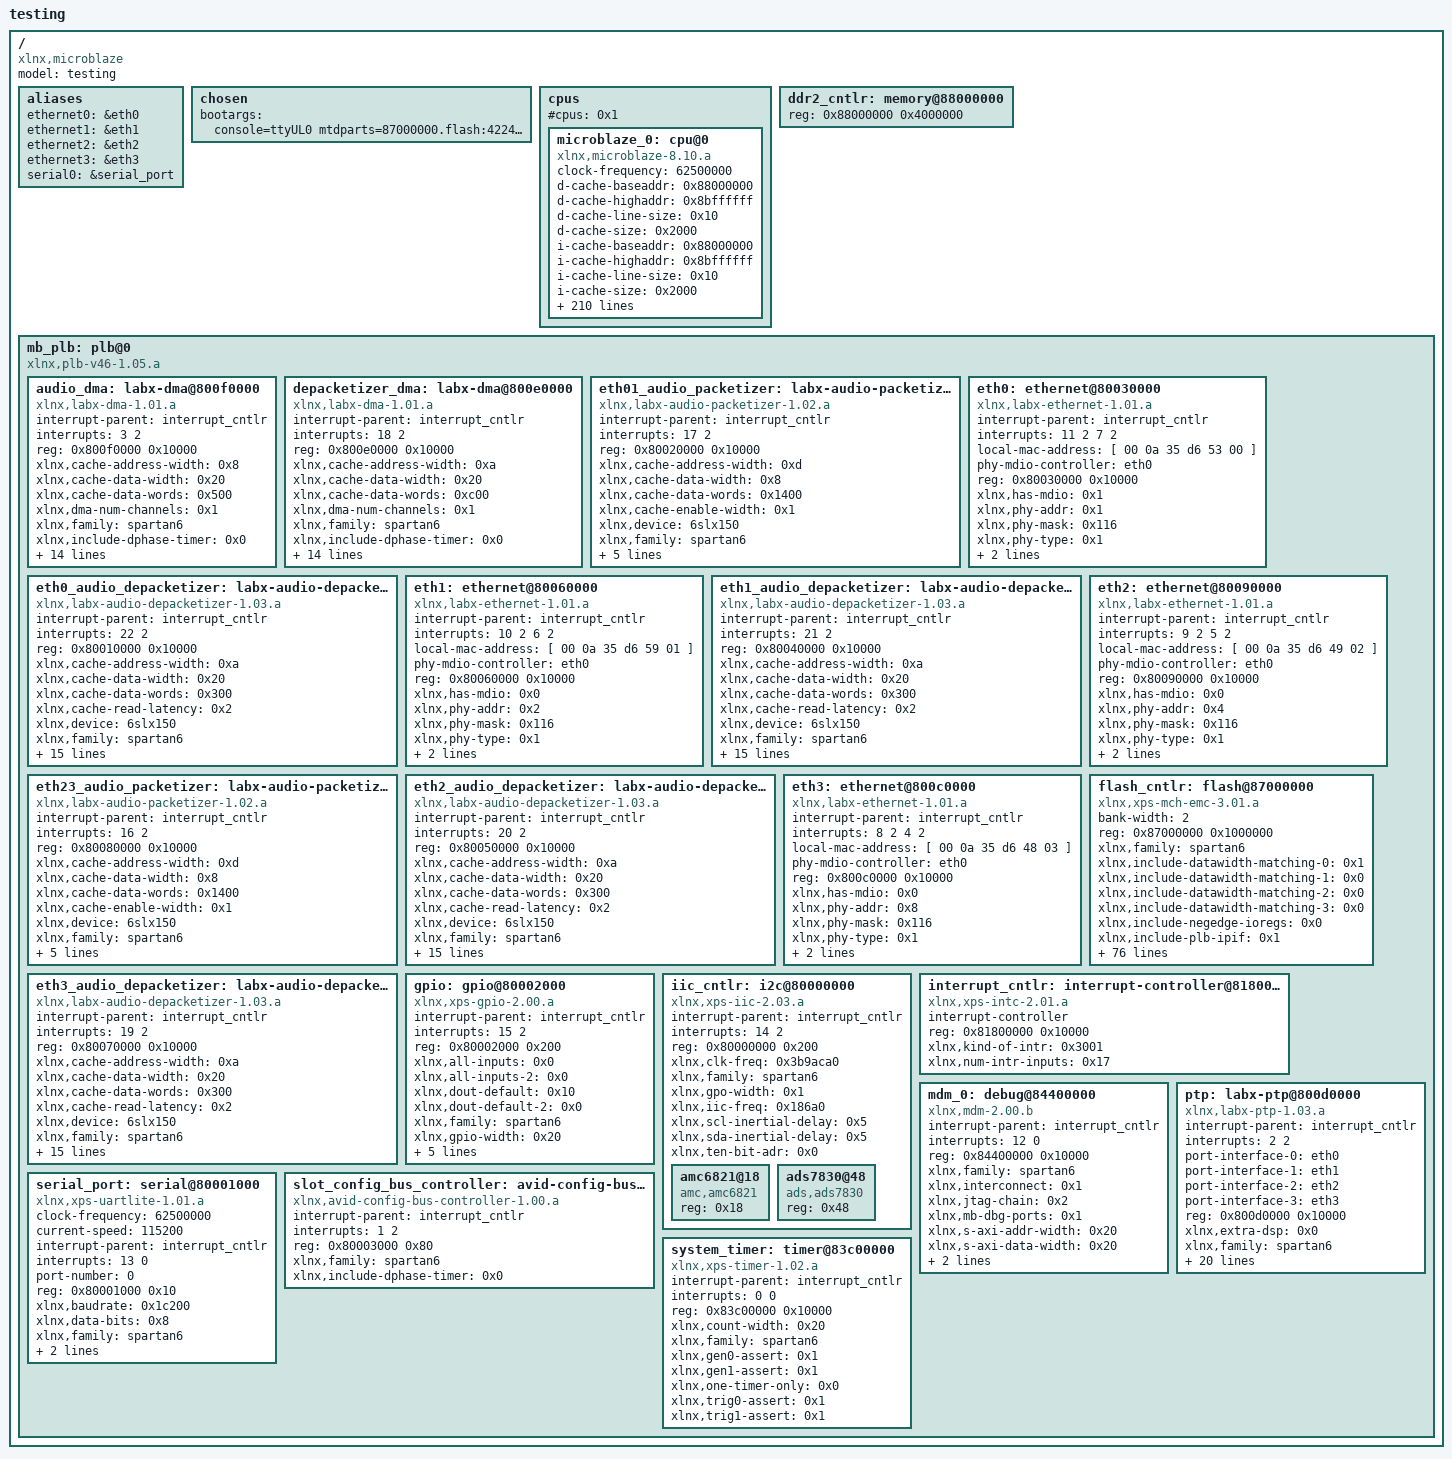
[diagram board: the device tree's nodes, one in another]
/*
 * Device Tree Generator version: 1.3
 *
 * (C) Copyright 2007-2008 Xilinx, Inc.
 * (C) Copyright 2007-2009 Michal Simek
 *
 * Michal SIMEK <monstr@monstr.eu>
 *
 * This program is free software; you can redistribute it and/or
 * modify it under the terms of the GNU General Public License as
 * published by the Free Software Foundation; either version 2 of
 * the License, or (at your option) any later version.
 *
 * This program is distributed in the hope that it will be useful,
 * but WITHOUT ANY WARRANTY; without even the implied warranty of
 * MERCHANTABILITY or FITNESS FOR A PARTICULAR PURPOSE. See the
 * GNU General Public License for more details.
 *
 * You should have received a copy of the GNU General Public License
 * along with this program; if not, write to the Free Software
 * Foundation, Inc., 59 Temple Place, Suite 330, Boston,
 * MA 02111-1307 USA
 *
 * CAUTION: This file is automatically generated by libgen.
 * Version: Xilinx EDK 13.1 EDK_O.40d
 *
 */

/dts-v1/;
/ {
	#address-cells = <1>;
	#size-cells = <1>;
	compatible = "xlnx,microblaze";
	model = "testing";
	aliases {
		ethernet0 = &eth0;
		ethernet1 = &eth1;
		ethernet2 = &eth2;
		ethernet3 = &eth3;
		serial0 = &serial_port;
	} ;
	chosen {
		bootargs = "console=ttyUL0 mtdparts=87000000.flash:4224K(fpga),256K(boot),128K(fdt),3712K(image),1920K(rootfs),3968K(romfs),2048K(settingsfs),32K(bootenv) root=mtd4 rootfstype=romfs init=/bin/init broadcom.led_default=0,0,-1,-1";
	} ;
	cpus {
		#address-cells = <1>;
		#cpus = <0x1>;
		#size-cells = <0>;
		microblaze_0: cpu@0 {
			clock-frequency = <62500000>;
			compatible = "xlnx,microblaze-8.10.a";
			d-cache-baseaddr = <0x88000000>;
			d-cache-highaddr = <0x8bffffff>;
			d-cache-line-size = <0x10>;
			d-cache-size = <0x2000>;
			device_type = "cpu";
			i-cache-baseaddr = <0x88000000>;
			i-cache-highaddr = <0x8bffffff>;
			i-cache-line-size = <0x10>;
			i-cache-size = <0x2000>;
			model = "microblaze,8.10.a";
			reg = <0>;
			timebase-frequency = <62500000>;
			xlnx,addr-tag-bits = <0xd>;
			xlnx,allow-dcache-wr = <0x1>;
			xlnx,allow-icache-wr = <0x1>;
			xlnx,archiver = "0";
			xlnx,area-optimized = <0x0>;
			xlnx,branch-target-cache-size = <0x0>;
			xlnx,cache-byte-size = <0x2000>;
			xlnx,compiler = "0";
			xlnx,compiler-flags = "0";
			xlnx,core-clock-freq-hz = <0x5f5e100>;
			xlnx,d-axi = <0x0>;
			xlnx,d-lmb = <0x1>;
			xlnx,d-plb = <0x1>;
			xlnx,data-size = <0x20>;
			xlnx,dcache-addr-tag = <0xd>;
			xlnx,dcache-always-used = <0x1>;
			xlnx,dcache-byte-size = <0x2000>;
			xlnx,dcache-data-width = <0x0>;
			xlnx,dcache-force-tag-lutram = <0x0>;
			xlnx,dcache-interface = <0x0>;
			xlnx,dcache-line-len = <0x4>;
			xlnx,dcache-use-fsl = <0x1>;
			xlnx,dcache-use-writeback = <0x0>;
			xlnx,dcache-victims = <0x0>;
			xlnx,debug-enabled = <0x1>;
			xlnx,div-zero-exception = <0x1>;
			xlnx,dynamic-bus-sizing = <0x1>;
			xlnx,ecc-use-ce-exception = <0x0>;
			xlnx,edge-is-positive = <0x1>;
			xlnx,endianness = <0x0>;
			xlnx,extra-compiler-flags = "0";
			xlnx,family = "spartan6";
			xlnx,fault-tolerant = <0x0>;
			xlnx,fpu-exception = <0x0>;
			xlnx,freq = <0x3b9aca0>;
			xlnx,fsl-data-size = <0x20>;
			xlnx,fsl-exception = <0x0>;
			xlnx,fsl-links = <0x0>;
			xlnx,i-axi = <0x0>;
			xlnx,i-lmb = <0x1>;
			xlnx,i-plb = <0x1>;
			xlnx,icache-always-used = <0x1>;
			xlnx,icache-data-width = <0x0>;
			xlnx,icache-force-tag-lutram = <0x0>;
			xlnx,icache-interface = <0x0>;
			xlnx,icache-line-len = <0x4>;
			xlnx,icache-streams = <0x0>;
			xlnx,icache-use-fsl = <0x1>;
			xlnx,icache-victims = <0x0>;
			xlnx,ill-opcode-exception = <0x1>;
			xlnx,instance = "microblaze_0";
			xlnx,interconnect = <0x1>;
			xlnx,interconnect-m-axi-dc-read-issuing = <0x2>;
			xlnx,interconnect-m-axi-dc-write-issuing = <0x20>;
			xlnx,interconnect-m-axi-dp-read-issuing = <0x1>;
			xlnx,interconnect-m-axi-dp-write-issuing = <0x1>;
			xlnx,interconnect-m-axi-ic-read-issuing = <0x2>;
			xlnx,interconnect-m-axi-ip-read-issuing = <0x1>;
			xlnx,interrupt-is-edge = <0x0>;
			xlnx,m-axi-d-bus-exception = <0x0>;
			xlnx,m-axi-dc-addr-width = <0x20>;
			xlnx,m-axi-dc-aruser-width = <0x5>;
			xlnx,m-axi-dc-awuser-width = <0x5>;
			xlnx,m-axi-dc-buser-width = <0x1>;
			xlnx,m-axi-dc-data-width = <0x20>;
			xlnx,m-axi-dc-exclusive-access = <0x0>;
			xlnx,m-axi-dc-protocol = "AXI4";
			xlnx,m-axi-dc-ruser-width = <0x1>;
			xlnx,m-axi-dc-supports-narrow-burst = <0x0>;
			xlnx,m-axi-dc-supports-read = <0x1>;
			xlnx,m-axi-dc-supports-threads = <0x0>;
			xlnx,m-axi-dc-supports-user-signals = <0x1>;
			xlnx,m-axi-dc-supports-write = <0x1>;
			xlnx,m-axi-dc-thread-id-width = <0x1>;
			xlnx,m-axi-dc-user-value = <0x1f>;
			xlnx,m-axi-dc-wuser-width = <0x1>;
			xlnx,m-axi-dp-addr-width = <0x20>;
			xlnx,m-axi-dp-data-width = <0x20>;
			xlnx,m-axi-dp-exclusive-access = <0x0>;
			xlnx,m-axi-dp-protocol = "AXI4LITE";
			xlnx,m-axi-dp-supports-narrow-burst = <0x0>;
			xlnx,m-axi-dp-supports-read = <0x1>;
			xlnx,m-axi-dp-supports-threads = <0x0>;
			xlnx,m-axi-dp-supports-write = <0x1>;
			xlnx,m-axi-dp-thread-id-width = <0x1>;
			xlnx,m-axi-i-bus-exception = <0x0>;
			xlnx,m-axi-ic-addr-width = <0x20>;
			xlnx,m-axi-ic-aruser-width = <0x5>;
			xlnx,m-axi-ic-awuser-width = <0x5>;
			xlnx,m-axi-ic-buser-width = <0x1>;
			xlnx,m-axi-ic-data-width = <0x20>;
			xlnx,m-axi-ic-protocol = "AXI4";
			xlnx,m-axi-ic-ruser-width = <0x1>;
			xlnx,m-axi-ic-supports-narrow-burst = <0x0>;
			xlnx,m-axi-ic-supports-read = <0x1>;
			xlnx,m-axi-ic-supports-threads = <0x0>;
			xlnx,m-axi-ic-supports-user-signals = <0x1>;
			xlnx,m-axi-ic-supports-write = <0x0>;
			xlnx,m-axi-ic-thread-id-width = <0x1>;
			xlnx,m-axi-ic-user-value = <0x1f>;
			xlnx,m-axi-ic-wuser-width = <0x1>;
			xlnx,m-axi-ip-addr-width = <0x20>;
			xlnx,m-axi-ip-data-width = <0x20>;
			xlnx,m-axi-ip-protocol = "AXI4LITE";
			xlnx,m-axi-ip-supports-narrow-burst = <0x0>;
			xlnx,m-axi-ip-supports-read = <0x1>;
			xlnx,m-axi-ip-supports-threads = <0x0>;
			xlnx,m-axi-ip-supports-write = <0x0>;
			xlnx,m-axi-ip-thread-id-width = <0x1>;
			xlnx,m0-axis-data-width = <0x20>;
			xlnx,m0-axis-protocol = "GENERIC";
			xlnx,m1-axis-data-width = <0x20>;
			xlnx,m1-axis-protocol = "GENERIC";
			xlnx,m10-axis-data-width = <0x20>;
			xlnx,m10-axis-protocol = "GENERIC";
			xlnx,m11-axis-data-width = <0x20>;
			xlnx,m11-axis-protocol = "GENERIC";
			xlnx,m12-axis-data-width = <0x20>;
			xlnx,m12-axis-protocol = "GENERIC";
			xlnx,m13-axis-data-width = <0x20>;
			xlnx,m13-axis-protocol = "GENERIC";
			xlnx,m14-axis-data-width = <0x20>;
			xlnx,m14-axis-protocol = "GENERIC";
			xlnx,m15-axis-data-width = <0x20>;
			xlnx,m15-axis-protocol = "GENERIC";
			xlnx,m2-axis-data-width = <0x20>;
			xlnx,m2-axis-protocol = "GENERIC";
			xlnx,m3-axis-data-width = <0x20>;
			xlnx,m3-axis-protocol = "GENERIC";
			xlnx,m4-axis-data-width = <0x20>;
			xlnx,m4-axis-protocol = "GENERIC";
			xlnx,m5-axis-data-width = <0x20>;
			xlnx,m5-axis-protocol = "GENERIC";
			xlnx,m6-axis-data-width = <0x20>;
			xlnx,m6-axis-protocol = "GENERIC";
			xlnx,m7-axis-data-width = <0x20>;
			xlnx,m7-axis-protocol = "GENERIC";
			xlnx,m8-axis-data-width = <0x20>;
			xlnx,m8-axis-protocol = "GENERIC";
			xlnx,m9-axis-data-width = <0x20>;
			xlnx,m9-axis-protocol = "GENERIC";
			xlnx,mmu-dtlb-size = <0x4>;
			xlnx,mmu-itlb-size = <0x2>;
			xlnx,mmu-privileged-instr = <0x0>;
			xlnx,mmu-tlb-access = <0x3>;
			xlnx,mmu-zones = <0x10>;
			xlnx,multiplier = "false";
			xlnx,number-of-pc-brk = <0x1>;
			xlnx,number-of-rd-addr-brk = <0x0>;
			xlnx,number-of-wr-addr-brk = <0x0>;
			xlnx,opcode-0x0-illegal = <0x1>;
			xlnx,optimization = <0x0>;
			xlnx,pvr = <0x0>;
			xlnx,pvr-user1 = <0x6>;
			xlnx,pvr-user2 = <0x0>;
			xlnx,reset-msr = <0x0>;
			xlnx,s0-axis-data-width = <0x20>;
			xlnx,s0-axis-protocol = "GENERIC";
			xlnx,s1-axis-data-width = <0x20>;
			xlnx,s1-axis-protocol = "GENERIC";
			xlnx,s10-axis-data-width = <0x20>;
			xlnx,s10-axis-protocol = "GENERIC";
			xlnx,s11-axis-data-width = <0x20>;
			xlnx,s11-axis-protocol = "GENERIC";
			xlnx,s12-axis-data-width = <0x20>;
			xlnx,s12-axis-protocol = "GENERIC";
			xlnx,s13-axis-data-width = <0x20>;
			xlnx,s13-axis-protocol = "GENERIC";
			xlnx,s14-axis-data-width = <0x20>;
			xlnx,s14-axis-protocol = "GENERIC";
			xlnx,s15-axis-data-width = <0x20>;
			xlnx,s15-axis-protocol = "GENERIC";
			xlnx,s2-axis-data-width = <0x20>;
			xlnx,s2-axis-protocol = "GENERIC";
			xlnx,s3-axis-data-width = <0x20>;
			xlnx,s3-axis-protocol = "GENERIC";
			xlnx,s4-axis-data-width = <0x20>;
			xlnx,s4-axis-protocol = "GENERIC";
			xlnx,s5-axis-data-width = <0x20>;
			xlnx,s5-axis-protocol = "GENERIC";
			xlnx,s6-axis-data-width = <0x20>;
			xlnx,s6-axis-protocol = "GENERIC";
			xlnx,s7-axis-data-width = <0x20>;
			xlnx,s7-axis-protocol = "GENERIC";
			xlnx,s8-axis-data-width = <0x20>;
			xlnx,s8-axis-protocol = "GENERIC";
			xlnx,s9-axis-data-width = <0x20>;
			xlnx,s9-axis-protocol = "GENERIC";
			xlnx,sco = <0x0>;
			xlnx,stream-interconnect = <0x0>;
			xlnx,unaligned-exceptions = <0x1>;
			xlnx,use-barrel = <0x1>;
			xlnx,use-branch-target-cache = <0x0>;
			xlnx,use-dcache = <0x1>;
			xlnx,use-div = <0x1>;
			xlnx,use-ext-brk = <0x1>;
			xlnx,use-ext-nm-brk = <0x1>;
			xlnx,use-extended-fsl-instr = <0x0>;
			xlnx,use-fpu = <0x0>;
			xlnx,use-hw-mul = <0x1>;
			xlnx,use-icache = <0x1>;
			xlnx,use-interrupt = <0x1>;
			xlnx,use-mmu = <0x0>;
			xlnx,use-msr-instr = <0x1>;
			xlnx,use-pcmp-instr = <0x1>;
			xlnx,use-stack-protection = <0x0>;
			xlnx,xmdstub-peripheral = "false";
		} ;
	} ;
	ddr2_cntlr: memory@88000000 {
		device_type = "memory";
		reg = < 0x88000000 0x4000000 >;
	} ;
	mb_plb: plb@0 {
		#address-cells = <1>;
		#size-cells = <1>;
		compatible = "xlnx,plb-v46-1.05.a", "xlnx,plb-v46-1.00.a", "simple-bus";
		ranges ;
		audio_dma: labx-dma@800f0000 {
			compatible = "xlnx,labx-dma-1.01.a";
			interrupt-parent = <&interrupt_cntlr>;
			interrupts = < 3 2 >;
			reg = < 0x800f0000 0x10000 >;
			xlnx,cache-address-width = <0x8>;
			xlnx,cache-data-width = <0x20>;
			xlnx,cache-data-words = <0x500>;
			xlnx,dma-num-channels = <0x1>;
			xlnx,family = "spartan6";
			xlnx,include-dphase-timer = <0x0>;
			xlnx,interface-type = "DMA_NPI";
			xlnx,internal-params = <0x1>;
			xlnx,microcode-words = <0x0>;
			xlnx,mplb-awidth = <0x20>;
			xlnx,mplb-clk-period-ps = <0x2710>;
			xlnx,mplb-dwidth = <0x80>;
			xlnx,mplb-native-dwidth = <0x20>;
			xlnx,mplb-p2p = <0x0>;
			xlnx,mplb-smallest-slave = <0x20>;
			xlnx,num-cache-interfaces = <0x5>;
			xlnx,num-param-interfaces = <0x1>;
			xlnx,param-address-width = <0x2>;
			xlnx,param-words = <0x4>;
			xlnx,parameter-interlock-fifo = <0x0>;
		} ;
		depacketizer_dma: labx-dma@800e0000 {
			compatible = "xlnx,labx-dma-1.01.a";
			interrupt-parent = <&interrupt_cntlr>;
			interrupts = < 18 2 >;
			reg = < 0x800e0000 0x10000 >;
			xlnx,cache-address-width = <0xa>;
			xlnx,cache-data-width = <0x20>;
			xlnx,cache-data-words = <0xc00>;
			xlnx,dma-num-channels = <0x1>;
			xlnx,family = "spartan6";
			xlnx,include-dphase-timer = <0x0>;
			xlnx,interface-type = "DMA_NPI";
			xlnx,internal-params = <0x1>;
			xlnx,microcode-words = <0xffffffff>;
			xlnx,mplb-awidth = <0x20>;
			xlnx,mplb-clk-period-ps = <0x2710>;
			xlnx,mplb-dwidth = <0x80>;
			xlnx,mplb-native-dwidth = <0x20>;
			xlnx,mplb-p2p = <0x0>;
			xlnx,mplb-smallest-slave = <0x20>;
			xlnx,num-cache-interfaces = <0x4>;
			xlnx,num-param-interfaces = <0x4>;
			xlnx,param-address-width = <0x9>;
			xlnx,param-words = <0x200>;
			xlnx,parameter-interlock-fifo = <0x1>;
		} ;
		eth01_audio_packetizer: labx-audio-packetizer@80020000 {
			compatible = "xlnx,labx-audio-packetizer-1.02.a";
			interrupt-parent = <&interrupt_cntlr>;
			interrupts = < 17 2 >;
			reg = < 0x80020000 0x10000 >;
			xlnx,cache-address-width = <0xd>;
			xlnx,cache-data-width = <0x8>;
			xlnx,cache-data-words = <0x1400>;
			xlnx,cache-enable-width = <0x1>;
			xlnx,device = "6slx150";
			xlnx,family = "spartan6";
			xlnx,has-internal-cache-ram = <0x0>;
			xlnx,include-dphase-timer = <0x0>;
			xlnx,is-dual-headed = <0x1>;
			xlnx,num-clock-domains = <0x1>;
			xlnx,package = "fgg484";
		} ;
		eth0: ethernet@80030000 {
			compatible = "xlnx,labx-ethernet-1.01.a";
			device_type = "network";
			interrupt-parent = <&interrupt_cntlr>;
			interrupts = < 11 2 7 2 >;
			local-mac-address = [ 00 0a 35 d6 53 00 ];
			phy-mdio-controller = <&eth0>;
			reg = < 0x80030000 0x10000 >;
			xlnx,has-mdio = <0x1>;
			xlnx,phy-addr = <0x1>;
			xlnx,phy-mask = <0x116>;
			xlnx,phy-type = <0x1>;
			xlnx,rxcsum = <0x0>;
			xlnx,txcsum = <0x0>;
		} ;
		eth0_audio_depacketizer: labx-audio-depacketizer@80010000 {
			compatible = "xlnx,labx-audio-depacketizer-1.03.a";
			interrupt-parent = <&interrupt_cntlr>;
			interrupts = < 22 2 >;
			reg = < 0x80010000 0x10000 >;
			xlnx,cache-address-width = <0xa>;
			xlnx,cache-data-width = <0x20>;
			xlnx,cache-data-words = <0x300>;
			xlnx,cache-read-latency = <0x2>;
			xlnx,device = "6slx150";
			xlnx,family = "spartan6";
			xlnx,has-suppress-inputs = <0x0>;
			xlnx,include-dphase-timer = <0x0>;
			xlnx,interface-type = "CACHE_RAM";
			xlnx,is-mcr-host = <0x1>;
			xlnx,mplb-awidth = <0x20>;
			xlnx,mplb-clk-period-ps = <0x2710>;
			xlnx,mplb-dwidth = <0x80>;
			xlnx,mplb-native-dwidth = <0x20>;
			xlnx,mplb-p2p = <0x0>;
			xlnx,mplb-smallest-slave = <0x20>;
			xlnx,npi-data-width = <0x20>;
			xlnx,num-clock-domains = <0x1>;
			xlnx,num-streams = <0x8>;
			xlnx,package = "fgg484";
			xlnx,param-address-width = <0x9>;
		} ;
		eth1: ethernet@80060000 {
			compatible = "xlnx,labx-ethernet-1.01.a";
			device_type = "network";
			interrupt-parent = <&interrupt_cntlr>;
			interrupts = < 10 2 6 2 >;
			local-mac-address = [ 00 0a 35 d6 59 01 ];
			phy-mdio-controller = <&eth0>;
			reg = < 0x80060000 0x10000 >;
			xlnx,has-mdio = <0x0>;
			xlnx,phy-addr = <0x2>;
			xlnx,phy-mask = <0x116>;
			xlnx,phy-type = <0x1>;
			xlnx,rxcsum = <0x0>;
			xlnx,txcsum = <0x0>;
		} ;
		eth1_audio_depacketizer: labx-audio-depacketizer@80040000 {
			compatible = "xlnx,labx-audio-depacketizer-1.03.a";
			interrupt-parent = <&interrupt_cntlr>;
			interrupts = < 21 2 >;
			reg = < 0x80040000 0x10000 >;
			xlnx,cache-address-width = <0xa>;
			xlnx,cache-data-width = <0x20>;
			xlnx,cache-data-words = <0x300>;
			xlnx,cache-read-latency = <0x2>;
			xlnx,device = "6slx150";
			xlnx,family = "spartan6";
			xlnx,has-suppress-inputs = <0x0>;
			xlnx,include-dphase-timer = <0x0>;
			xlnx,interface-type = "CACHE_RAM";
			xlnx,is-mcr-host = <0x0>;
			xlnx,mplb-awidth = <0x20>;
			xlnx,mplb-clk-period-ps = <0x2710>;
			xlnx,mplb-dwidth = <0x80>;
			xlnx,mplb-native-dwidth = <0x20>;
			xlnx,mplb-p2p = <0x0>;
			xlnx,mplb-smallest-slave = <0x20>;
			xlnx,npi-data-width = <0x20>;
			xlnx,num-clock-domains = <0x1>;
			xlnx,num-streams = <0x8>;
			xlnx,package = "fgg484";
			xlnx,param-address-width = <0x9>;
		} ;
		eth23_audio_packetizer: labx-audio-packetizer@80080000 {
			compatible = "xlnx,labx-audio-packetizer-1.02.a";
			interrupt-parent = <&interrupt_cntlr>;
			interrupts = < 16 2 >;
			reg = < 0x80080000 0x10000 >;
			xlnx,cache-address-width = <0xd>;
			xlnx,cache-data-width = <0x8>;
			xlnx,cache-data-words = <0x1400>;
			xlnx,cache-enable-width = <0x1>;
			xlnx,device = "6slx150";
			xlnx,family = "spartan6";
			xlnx,has-internal-cache-ram = <0x0>;
			xlnx,include-dphase-timer = <0x0>;
			xlnx,is-dual-headed = <0x1>;
			xlnx,num-clock-domains = <0x1>;
			xlnx,package = "fgg484";
		} ;
		eth2: ethernet@80090000 {
			compatible = "xlnx,labx-ethernet-1.01.a";
			device_type = "network";
			interrupt-parent = <&interrupt_cntlr>;
			interrupts = < 9 2 5 2 >;
			local-mac-address = [ 00 0a 35 d6 49 02 ];
			phy-mdio-controller = <&eth0>;
			reg = < 0x80090000 0x10000 >;
			xlnx,has-mdio = <0x0>;
			xlnx,phy-addr = <0x4>;
			xlnx,phy-mask = <0x116>;
			xlnx,phy-type = <0x1>;
			xlnx,rxcsum = <0x0>;
			xlnx,txcsum = <0x0>;
		} ;
		eth2_audio_depacketizer: labx-audio-depacketizer@80050000 {
			compatible = "xlnx,labx-audio-depacketizer-1.03.a";
			interrupt-parent = <&interrupt_cntlr>;
			interrupts = < 20 2 >;
			reg = < 0x80050000 0x10000 >;
			xlnx,cache-address-width = <0xa>;
			xlnx,cache-data-width = <0x20>;
			xlnx,cache-data-words = <0x300>;
			xlnx,cache-read-latency = <0x2>;
			xlnx,device = "6slx150";
			xlnx,family = "spartan6";
			xlnx,has-suppress-inputs = <0x0>;
			xlnx,include-dphase-timer = <0x0>;
			xlnx,interface-type = "CACHE_RAM";
			xlnx,is-mcr-host = <0x0>;
			xlnx,mplb-awidth = <0x20>;
			xlnx,mplb-clk-period-ps = <0x2710>;
			xlnx,mplb-dwidth = <0x80>;
			xlnx,mplb-native-dwidth = <0x20>;
			xlnx,mplb-p2p = <0x0>;
			xlnx,mplb-smallest-slave = <0x20>;
			xlnx,npi-data-width = <0x20>;
			xlnx,num-clock-domains = <0x1>;
			xlnx,num-streams = <0x8>;
			xlnx,package = "fgg484";
			xlnx,param-address-width = <0x9>;
		} ;
		eth3: ethernet@800c0000 {
			compatible = "xlnx,labx-ethernet-1.01.a";
			device_type = "network";
			interrupt-parent = <&interrupt_cntlr>;
			interrupts = < 8 2 4 2 >;
			local-mac-address = [ 00 0a 35 d6 48 03 ];
			phy-mdio-controller = <&eth0>;
			reg = < 0x800c0000 0x10000 >;
			xlnx,has-mdio = <0x0>;
			xlnx,phy-addr = <0x8>;
			xlnx,phy-mask = <0x116>;
			xlnx,phy-type = <0x1>;
			xlnx,rxcsum = <0x0>;
			xlnx,txcsum = <0x0>;
		} ;
		eth3_audio_depacketizer: labx-audio-depacketizer@80070000 {
			compatible = "xlnx,labx-audio-depacketizer-1.03.a";
			interrupt-parent = <&interrupt_cntlr>;
			interrupts = < 19 2 >;
			reg = < 0x80070000 0x10000 >;
			xlnx,cache-address-width = <0xa>;
			xlnx,cache-data-width = <0x20>;
			xlnx,cache-data-words = <0x300>;
			xlnx,cache-read-latency = <0x2>;
			xlnx,device = "6slx150";
			xlnx,family = "spartan6";
			xlnx,has-suppress-inputs = <0x0>;
			xlnx,include-dphase-timer = <0x0>;
			xlnx,interface-type = "CACHE_RAM";
			xlnx,is-mcr-host = <0x0>;
			xlnx,mplb-awidth = <0x20>;
			xlnx,mplb-clk-period-ps = <0x2710>;
			xlnx,mplb-dwidth = <0x80>;
			xlnx,mplb-native-dwidth = <0x20>;
			xlnx,mplb-p2p = <0x0>;
			xlnx,mplb-smallest-slave = <0x20>;
			xlnx,npi-data-width = <0x20>;
			xlnx,num-clock-domains = <0x1>;
			xlnx,num-streams = <0x8>;
			xlnx,package = "fgg484";
			xlnx,param-address-width = <0x9>;
		} ;
		flash_cntlr: flash@87000000 {
			bank-width = <2>;
			compatible = "xlnx,xps-mch-emc-3.01.a", "cfi-flash";
			reg = < 0x87000000 0x1000000 >;
			xlnx,family = "spartan6";
			xlnx,include-datawidth-matching-0 = <0x1>;
			xlnx,include-datawidth-matching-1 = <0x0>;
			xlnx,include-datawidth-matching-2 = <0x0>;
			xlnx,include-datawidth-matching-3 = <0x0>;
			xlnx,include-negedge-ioregs = <0x0>;
			xlnx,include-plb-ipif = <0x1>;
			xlnx,include-wrbuf = <0x1>;
			xlnx,max-mem-width = <0x10>;
			xlnx,mch-native-dwidth = <0x20>;
			xlnx,mch-splb-awidth = <0x20>;
			xlnx,mch-splb-clk-period-ps = <0x3e80>;
			xlnx,mch0-accessbuf-depth = <0x10>;
			xlnx,mch0-protocol = <0x0>;
			xlnx,mch0-rddatabuf-depth = <0x10>;
			xlnx,mch1-accessbuf-depth = <0x10>;
			xlnx,mch1-protocol = <0x0>;
			xlnx,mch1-rddatabuf-depth = <0x10>;
			xlnx,mch2-accessbuf-depth = <0x10>;
			xlnx,mch2-protocol = <0x0>;
			xlnx,mch2-rddatabuf-depth = <0x10>;
			xlnx,mch3-accessbuf-depth = <0x10>;
			xlnx,mch3-protocol = <0x0>;
			xlnx,mch3-rddatabuf-depth = <0x10>;
			xlnx,mem0-width = <0x10>;
			xlnx,mem1-width = <0x20>;
			xlnx,mem2-width = <0x20>;
			xlnx,mem3-width = <0x20>;
			xlnx,num-banks-mem = <0x1>;
			xlnx,num-channels = <0x0>;
			xlnx,pagemode-flash-0 = <0x0>;
			xlnx,pagemode-flash-1 = <0x0>;
			xlnx,pagemode-flash-2 = <0x0>;
			xlnx,pagemode-flash-3 = <0x0>;
			xlnx,priority-mode = <0x0>;
			xlnx,synch-mem-0 = <0x0>;
			xlnx,synch-mem-1 = <0x0>;
			xlnx,synch-mem-2 = <0x0>;
			xlnx,synch-mem-3 = <0x0>;
			xlnx,synch-pipedelay-0 = <0x2>;
			xlnx,synch-pipedelay-1 = <0x2>;
			xlnx,synch-pipedelay-2 = <0x2>;
			xlnx,synch-pipedelay-3 = <0x2>;
			xlnx,tavdv-ps-mem-0 = <0x11170>;
			xlnx,tavdv-ps-mem-1 = <0x3a98>;
			xlnx,tavdv-ps-mem-2 = <0x3a98>;
			xlnx,tavdv-ps-mem-3 = <0x3a98>;
			xlnx,tcedv-ps-mem-0 = <0x11170>;
			xlnx,tcedv-ps-mem-1 = <0x3a98>;
			xlnx,tcedv-ps-mem-2 = <0x3a98>;
			xlnx,tcedv-ps-mem-3 = <0x3a98>;
			xlnx,thzce-ps-mem-0 = <0x61a8>;
			xlnx,thzce-ps-mem-1 = <0x1b58>;
			xlnx,thzce-ps-mem-2 = <0x1b58>;
			xlnx,thzce-ps-mem-3 = <0x1b58>;
			xlnx,thzoe-ps-mem-0 = <0x61a8>;
			xlnx,thzoe-ps-mem-1 = <0x1b58>;
			xlnx,thzoe-ps-mem-2 = <0x1b58>;
			xlnx,thzoe-ps-mem-3 = <0x1b58>;
			xlnx,tlzwe-ps-mem-0 = <0x1388>;
			xlnx,tlzwe-ps-mem-1 = <0x0>;
			xlnx,tlzwe-ps-mem-2 = <0x0>;
			xlnx,tlzwe-ps-mem-3 = <0x0>;
			xlnx,tpacc-ps-flash-0 = <0x61a8>;
			xlnx,tpacc-ps-flash-1 = <0x61a8>;
			xlnx,tpacc-ps-flash-2 = <0x61a8>;
			xlnx,tpacc-ps-flash-3 = <0x61a8>;
			xlnx,twc-ps-mem-0 = <0x11170>;
			xlnx,twc-ps-mem-1 = <0x3a98>;
			xlnx,twc-ps-mem-2 = <0x3a98>;
			xlnx,twc-ps-mem-3 = <0x3a98>;
			xlnx,twp-ps-mem-0 = <0xafc8>;
			xlnx,twp-ps-mem-1 = <0x2ee0>;
			xlnx,twp-ps-mem-2 = <0x2ee0>;
			xlnx,twp-ps-mem-3 = <0x2ee0>;
			xlnx,xcl0-linesize = <0x4>;
			xlnx,xcl0-writexfer = <0x1>;
			xlnx,xcl1-linesize = <0x4>;
			xlnx,xcl1-writexfer = <0x1>;
			xlnx,xcl2-linesize = <0x4>;
			xlnx,xcl2-writexfer = <0x1>;
			xlnx,xcl3-linesize = <0x4>;
			xlnx,xcl3-writexfer = <0x1>;
		} ;
		gpio: gpio@80002000 {
			compatible = "xlnx,xps-gpio-2.00.a", "xlnx,xps-gpio-1.00.a";
			interrupt-parent = <&interrupt_cntlr>;
			interrupts = < 15 2 >;
			reg = < 0x80002000 0x200 >;
			xlnx,all-inputs = <0x0>;
			xlnx,all-inputs-2 = <0x0>;
			xlnx,dout-default = <0x10>;
			xlnx,dout-default-2 = <0x0>;
			xlnx,family = "spartan6";
			xlnx,gpio-width = <0x20>;
			xlnx,gpio2-width = <0x20>;
			xlnx,interrupt-present = <0x1>;
			xlnx,is-dual = <0x1>;
			xlnx,tri-default = <0xffffffff>;
			xlnx,tri-default-2 = <0xffffffff>;
		} ;
		iic_cntlr: i2c@80000000 {
			compatible = "xlnx,xps-iic-2.03.a", "xlnx,xps-iic-2.00.a";
			interrupt-parent = <&interrupt_cntlr>;
			interrupts = < 14 2 >;
			reg = < 0x80000000 0x200 >;
			xlnx,clk-freq = <0x3b9aca0>;
			xlnx,family = "spartan6";
			xlnx,gpo-width = <0x1>;
			xlnx,iic-freq = <0x186a0>;
			xlnx,scl-inertial-delay = <0x5>;
			xlnx,sda-inertial-delay = <0x5>;
			xlnx,ten-bit-adr = <0x0>;
			amc6821@18 {
				compatible = "amc,amc6821";
				reg = <0x18>;
			};
			ads7830@48 {
				compatible = "ads,ads7830";
				reg = <0x48>;
			};
		} ;
		interrupt_cntlr: interrupt-controller@81800000 {
			#interrupt-cells = <0x2>;
			compatible = "xlnx,xps-intc-2.01.a", "xlnx,xps-intc-1.00.a";
			interrupt-controller ;
			reg = < 0x81800000 0x10000 >;
			xlnx,kind-of-intr = <0x3001>;
			xlnx,num-intr-inputs = <0x17>;
		} ;
		mdm_0: debug@84400000 {
			compatible = "xlnx,mdm-2.00.b";
			interrupt-parent = <&interrupt_cntlr>;
			interrupts = < 12 0 >;
			reg = < 0x84400000 0x10000 >;
			xlnx,family = "spartan6";
			xlnx,interconnect = <0x1>;
			xlnx,jtag-chain = <0x2>;
			xlnx,mb-dbg-ports = <0x1>;
			xlnx,s-axi-addr-width = <0x20>;
			xlnx,s-axi-data-width = <0x20>;
			xlnx,s-axi-protocol = "AXI4LITE";
			xlnx,use-uart = <0x1>;
		} ;
		ptp: labx-ptp@800d0000 {
			compatible = "xlnx,labx-ptp-1.03.a";
			interrupt-parent = <&interrupt_cntlr>;
			interrupts = < 2 2 >;
			port-interface-0 = <&eth0>;
			port-interface-1 = <&eth1>;
			port-interface-2 = <&eth2>;
			port-interface-3 = <&eth3>;
			reg = < 0x800d0000 0x10000 >;
			xlnx,extra-dsp = <0x0>;
			xlnx,family = "spartan6";
			xlnx,include-dphase-timer = <0x0>;
			xlnx,nominal-increment-fraction = <0x0>;
			xlnx,nominal-increment-mantissa = <0x8>;
			xlnx,num-ports = <0x4>;
			xlnx,phy-mac-rx-delay = <0x0>;
			xlnx,phy-mac-tx-delay = <0x0>;
			xlnx,port-interface-0 = "eth0";
			xlnx,port-interface-1 = "eth1";
			xlnx,port-interface-2 = "eth2";
			xlnx,port-interface-3 = "eth3";
			xlnx,port-interface-4 = "Invalid";
			xlnx,port-interface-5 = "Invalid";
			xlnx,port-interface-6 = "Invalid";
			xlnx,port-interface-7 = "Invalid";
			xlnx,port-width = <0x8>;
			xlnx,rtc-d-coefficient = <0x0>;
			xlnx,rtc-i-coefficient = <0x0>;
			xlnx,rtc-p-coefficient = <0x0>;
			xlnx,timer-divider = <0x271>;
			xlnx,timer-prescaler = <0x3e8>;
		} ;
		serial_port: serial@80001000 {
			clock-frequency = <62500000>;
			compatible = "xlnx,xps-uartlite-1.01.a", "xlnx,xps-uartlite-1.00.a";
			current-speed = <115200>;
			device_type = "serial";
			interrupt-parent = <&interrupt_cntlr>;
			interrupts = < 13 0 >;
			port-number = <0>;
			reg = < 0x80001000 0x10 >;
			xlnx,baudrate = <0x1c200>;
			xlnx,data-bits = <0x8>;
			xlnx,family = "spartan6";
			xlnx,odd-parity = <0x1>;
			xlnx,use-parity = <0x0>;
		} ;
		slot_config_bus_controller: avid-config-bus-controller@80003000 {
			compatible = "xlnx,avid-config-bus-controller-1.00.a";
			interrupt-parent = <&interrupt_cntlr>;
			interrupts = < 1 2 >;
			reg = < 0x80003000 0x80 >;
			xlnx,family = "spartan6";
			xlnx,include-dphase-timer = <0x0>;
		} ;
		system_timer: timer@83c00000 {
			compatible = "xlnx,xps-timer-1.02.a", "xlnx,xps-timer-1.00.a";
			interrupt-parent = <&interrupt_cntlr>;
			interrupts = < 0 0 >;
			reg = < 0x83c00000 0x10000 >;
			xlnx,count-width = <0x20>;
			xlnx,family = "spartan6";
			xlnx,gen0-assert = <0x1>;
			xlnx,gen1-assert = <0x1>;
			xlnx,one-timer-only = <0x0>;
			xlnx,trig0-assert = <0x1>;
			xlnx,trig1-assert = <0x1>;
		} ;
	} ;
}  ;
